# SAMA7D65D2GN8 register map
Vendor: Microchip Technology; Series: SAMA7D6; File version: 0
Registers are 32-bit, read-write, reset 0x0 unless marked. A register's access mark holds for its fields unless they carry their own. Offsets are from the block's base; [hi:lo] are bit positions; {n}, {i} and the like mark numbered series; 'fields as' and 'values as' point back to an identical list.

## SSC0 — Synchronous Serial Controller
Base 0xE180C000; register names take the prefix SSC_
Same registers: SSC1 0xE2010000
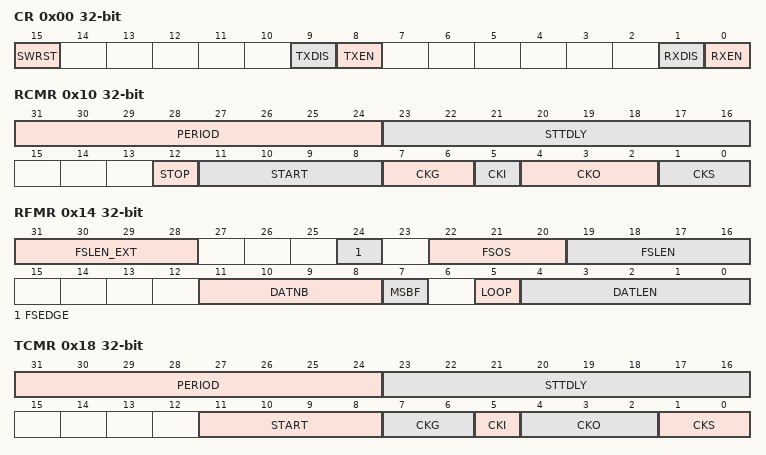
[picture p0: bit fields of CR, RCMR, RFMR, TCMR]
0x00 CR wo — Control Register
  [15] SWRST — Software Reset
    0=No effect; 1=Performs a software reset. Has priority on any other bit in SSC_CR.
  [9] TXDIS — Transmit Disable
    0=No effect; 1=Disables Transmit. If a character is currently being transmitted, disables at end of current character transmission.
  [8] TXEN — Transmit Enable
    0=No effect; 1=Enables Transmit if TXDIS is not set
  [1] RXDIS — Receive Disable
    0=No effect; 1=Disables Receive. If a character is currently being received, disables at end of current character reception.
  [0] RXEN — Receive Enable
    0=No effect; 1=Enables Receive if RXDIS is not set
0x04 CMR — Clock Mode Register
  [11:0] DIV — Clock Divider
    0=The Clock Divider is not active
0x10 RCMR — Receive Clock Mode Register
  [31:24] PERIOD — Receive Period Divider Selection
  [23:16] STTDLY — Receive Start Delay
  [12] STOP — Receive Stop Selection
    0=After completion of a data transfer when starting with a Compare 0, the receiver stops the data transfer and waits for a new compare 0; 1=After starting a receive with a Compare 0, the receiver operates in a continuous mode until a Compare 1 is detected
  [11:8] START — Receive Start Selection
    0=CONTINUOUS (Continuous, as soon as the receiver is enabled, and immediately after the end of transfer of the previous data.); 1=TRANSMIT (Transmit start); 2=RF_LOW (Detection of a low level on RF signal); 3=RF_HIGH (Detection of a high level on RF signal); 4=RF_FALLING (Detection of a falling edge on RF signal); 5=RF_RISING (Detection of a rising edge on RF signal); 6=RF_LEVEL (Detection of any level change on RF signal); 7=RF_EDGE (Detection of any edge on RF signal); 8=CMP_0 (Compare 0)
  [7:6] CKG — Receive Clock Gating Selection
    0=CONTINUOUS (None); 1=EN_RF_LOW (Receive Clock enabled only if RF Low); 2=EN_RF_HIGH (Receive Clock enabled only if RF High)
  [5] CKI — Receive Clock Inversion
    0=The data inputs (Data and Frame Sync signals) are sampled on Receive Clock falling edge. The Frame Sync signal output is shifted out on Receive Clock rising edge.; 1=The data inputs (Data and Frame Sync signals) are sampled on Receive Clock rising edge. The Frame Sync signal output is shifted out on Receive Clock falling edge.
  [4:2] CKO — Receive Clock Output Mode Selection
    0=NONE (None, RK pin is an input); 1=CONTINUOUS (Continuous Receive Clock, RK pin is an output); 2=TRANSFER (Receive Clock only during data transfers, RK pin is an output)
  [1:0] CKS — Receive Clock Selection
    0=MCK (Divided Clock); 1=TK (TK Clock signal); 2=RK (RK pin)
0x14 RFMR — Receive Frame Mode Register
  [31:28] FSLEN_EXT — FSLEN Field Extension
  [24] FSEDGE — Frame Sync Edge Detection
    0=POSITIVE (Positive Edge Detection); 1=NEGATIVE (Negative Edge Detection)
  [22:20] FSOS — Receive Frame Sync Output Selection
    0=NONE (None, RF pin is an input); 1=NEGATIVE (Negative Pulse, RF pin is an output); 2=POSITIVE (Positive Pulse, RF pin is an output); 3=LOW (Driven Low during data transfer, RF pin is an output); 4=HIGH (Driven High during data transfer, RF pin is an output); 5=TOGGLING (Toggling at each start of data transfer, RF pin is an output)
  [19:16] FSLEN — Receive Frame Sync Length
  [11:8] DATNB — Data Number per Frame
  [7] MSBF — Most Significant Bit First
    0=The lowest significant bit of the data register is sampled first in the bit stream; 1=The most significant bit of the data register is sampled first in the bit stream
  [5] LOOP — Loop Mode
    0=Normal operating mode; 1=RD is driven by TD, RF is driven by TF and TK drives RK
  [4:0] DATLEN — Data Length
    0=Forbidden value (1-bit data length not supported)
0x18 TCMR — Transmit Clock Mode Register
  [31:24] PERIOD — Transmit Period Divider Selection
  [23:16] STTDLY — Transmit Start Delay
  [11:8] START — Transmit Start Selection
    0=CONTINUOUS (Continuous, as soon as a word is written in the SSC_THFR (if Transmit is enabled), and immediately after the end of transfer of the previous data); 1=RECEIVE (Receive start); 2=TF_LOW (Detection of a low level on TF signal); 3=TF_HIGH (Detection of a high level on TF signal); 4=TF_FALLING (Detection of a falling edge on TF signal); 5=TF_RISING (Detection of a rising edge on TF signal); 6=TF_LEVEL (Detection of any level change on TF signal); 7=TF_EDGE (Detection of any edge on TF signal)
  [7:6] CKG — Transmit Clock Gating Selection
    0=CONTINUOUS (None); 1=EN_TF_LOW (Transmit Clock enabled only if TF Low); 2=EN_TF_HIGH (Transmit Clock enabled only if TF High)
  [5] CKI — Transmit Clock Inversion
    0=The data outputs (Data and Frame Sync signals) are shifted out on Transmit Clock falling edge. The Frame Sync signal input is sampled on Transmit Clock rising edge.; 1=The data outputs (Data and Frame Sync signals) are shifted out on Transmit Clock rising edge. The Frame Sync signal input is sampled on Transmit Clock falling edge.
  [4:2] CKO — Transmit Clock Output Mode Selection
    0=NONE (None, TK pin is an input); 1=CONTINUOUS (Continuous Transmit Clock, TK pin is an output); 2=TRANSFER (Transmit Clock only during data transfers, TK pin is an output)
  [1:0] CKS — Transmit Clock Selection
    0=MCK (Divided Clock); 1=RK (RK Clock signal); 2=TK (TK pin)
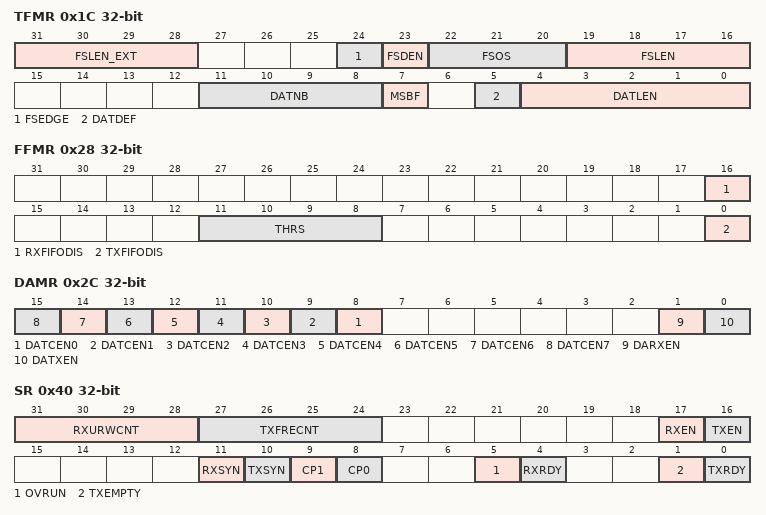
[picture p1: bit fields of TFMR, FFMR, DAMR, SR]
0x1C TFMR — Transmit Frame Mode Register
  [31:28] FSLEN_EXT — FSLEN Field Extension
  [24] FSEDGE — Frame Sync Edge Detection
    values as RFMR.FSEDGE
  [23] FSDEN — Frame Sync Data Enable
    0=The TD line is driven with the default value during the Transmit Frame Sync signal; 1=SSC_TSHR value is shifted out during the transmission of the Transmit Frame Sync signal
  [22:20] FSOS — Transmit Frame Sync Output Selection
    0=NONE (None, TF pin is an input); 1=NEGATIVE (Negative Pulse, TF pin is an output); 2=POSITIVE (Positive Pulse, TF pin is an output); 3=LOW (Driven Low during data transfer); 4=HIGH (Driven High during data transfer); 5=TOGGLING (Toggling at each start of data transfer)
  [19:16] FSLEN — Transmit Frame Sync Length
  [11:8] DATNB — Data Number per Frame
  [7] MSBF — Most Significant Bit First
    0=The lowest significant bit of the data register is shifted out first in the bit stream; 1=The most significant bit of the data register is shifted out first in the bit stream
  [5] DATDEF — Data Default Value
  [4:0] DATLEN — Data Length
    0=Forbidden value (1-bit data length not supported)
0x20 RHFR ro — Receive Holding FIFO Register
  [31:0] RDAT — Receive Data
0x24 THFR wo — Transmit Holding FIFO Register
  [31:0] TDAT — Transmit Data
0x28 FFMR — FIFO Mode Register
  [16] RXFIFODIS — Receive FIFO Disable
    0=The receive FIFO is enabled; 1=The receive FIFO is disabled. Only a single entry Receive Holding register is available instead.
  [11:8] THRS — Transmit Start Threshold
  [0] TXFIFODIS — Transmit FIFO Disable
    0=The transmit FIFO is enabled; 1=The transmit FIFO is disabled. Only a single entry Transmit Holding register is available instead.
0x2C DAMR — Direct Access Mode Register
  [n+8] DATCEN{n} (n=0..7) — Direct Access Transmit Channel {n} Enable
    0=Channel x from the ASRC direct audio stream is not transmitted on the SSC physical output line; 1=Channel x from the ASRC direct audio stream is transmitted on the SSC physical output line
  [1] DARXEN — Direct Access Receive Enable
    1=The ASRC can be directly loaded with the audio samples from the SSC physical output line without software or DMA intervention
  [0] DATXEN — Direct Access Transmit Enable
    1=The Asynchronous Sample Rate Converter (ASRC) can directly transmit the converted audio samples on the SSC physical output line without software or DMA intervention
0x30 RSHR ro — Receive Sync. Holding Register
  [15:0] RSDAT — Receive Synchronization Data
0x34 TSHR — Transmit Sync. Holding Register
  [15:0] TSDAT — Transmit Synchronization Data
0x38 RC0R — Receive Compare 0 Register
  [15:0] CP0 — Receive Compare Data 0
0x3C RC1R — Receive Compare 1 Register
  [15:0] CP1 — Receive Compare Data 1
0x40 SR ro — Status Register
  [31:28] RXURWCNT — Receive FIFO Unread Word Count
  [27:24] TXFRECNT — Transmit FIFO Free Entries Count
  [17] RXEN — Receive Enable
    0=Receive is disabled; 1=Receive is enabled
  [16] TXEN — Transmit Enable
    0=Transmit is disabled; 1=Transmit is enabled
  [11] RXSYN — Receive Sync
    0=No Rx Sync has occurred since the last read of the Status register; 1=An Rx Sync has occurred since the last read of the Status register
  [10] TXSYN — Transmit Sync
    0=No Tx Sync has occurred since the last read of the Status register; 1=A Tx Sync has occurred since the last read of the Status register
  [9] CP1 — Compare 1
    0=No compare 1 has occurred since the last read of the Status register; 1=A compare 1 has occurred since the last read of the Status register
  [8] CP0 — Compare 0
    0=No compare 0 has occurred since the last read of the Status register; 1=A compare 0 has occurred since the last read of the Status register
  [5] OVRUN — Receive Overrun
    0=No data has been loaded in SSC_RHFR while previous data has not been read since the last read of the Status register; 1=Data has been loaded in SSC_RHFR while previous data has not yet been read since the last read of the Status register
  [4] RXRDY — Receive Ready
    0=SSC_RHFR is empty; 1=Data has been received and loaded in SSC_RHFR
  [1] TXEMPTY — Transmit Empty
    0=Data remains in SSC_THFR or is currently transmitted from TSR; 1=Last data written in SSC_THFR has been loaded in TSR and last data loaded in TSR has been transmitted
  [0] TXRDY — Transmit Ready
    0=Data has been loaded in SSC_THFR and is waiting to be loaded in the Transmit Shift register (TSR); 1=SSC_THFR is empty
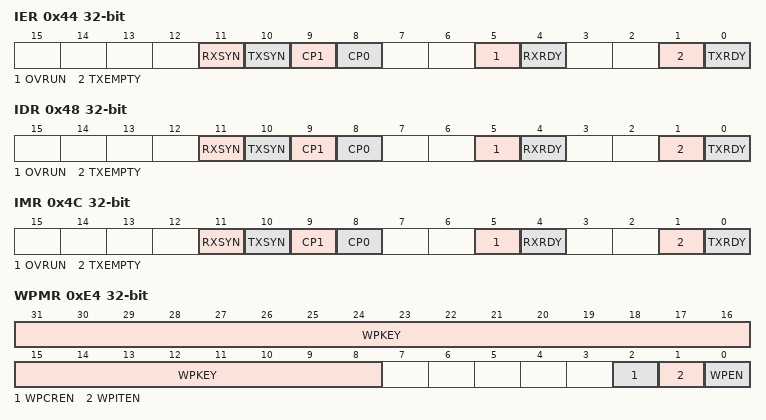
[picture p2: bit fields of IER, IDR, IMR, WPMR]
0x44 IER wo — Interrupt Enable Register
  [11] RXSYN — Rx Sync Interrupt Enable
  [10] TXSYN — Tx Sync Interrupt Enable
  [9] CP1 — Compare 1 Interrupt Enable
  [8] CP0 — Compare 0 Interrupt Enable
  [5] OVRUN — Receive Overrun Interrupt Enable
  [4] RXRDY — Receive Ready Interrupt Enable
  [1] TXEMPTY — Transmit Empty Interrupt Enable
  [0] TXRDY — Transmit Ready Interrupt Enable
0x48 IDR wo — Interrupt Disable Register
  [11] RXSYN — Rx Sync Interrupt Disable
  [10] TXSYN — Tx Sync Interrupt Disable
  [9] CP1 — Compare 1 Interrupt Disable
  [8] CP0 — Compare 0 Interrupt Disable
  [5] OVRUN — Receive Overrun Interrupt Disable
  [4] RXRDY — Receive Ready Interrupt Disable
  [1] TXEMPTY — Transmit Empty Interrupt Disable
  [0] TXRDY — Transmit Ready Interrupt Disable
0x4C IMR ro — Interrupt Mask Register
  [11] RXSYN — Rx Sync Interrupt Mask
  [10] TXSYN — Tx Sync Interrupt Mask
  [9] CP1 — Compare 1 Interrupt Mask
  [8] CP0 — Compare 0 Interrupt Mask
  [5] OVRUN — Receive Overrun Interrupt Mask
  [4] RXRDY — Receive Ready Interrupt Mask
  [1] TXEMPTY — Transmit Empty Interrupt Mask
  [0] TXRDY — Transmit Ready Interrupt Mask
0xE4 WPMR — Write Protection Mode Register
  [31:8] WPKEY — Write Protection Key
    0x535343=PASSWD (Writing any other value in this field aborts the write operation of the WPEN,WPITEN,WPCREN bits. Always reads as 0.)
  [2] WPCREN — Write Protection Control Enable
    0=Disables the write protection of the control register if WPKEY corresponds to 0x535343 ('SSC' in ASCII); 1=Enables the write protection of the control register if WPKEY corresponds to 0x535343 ('SSC' in ASCII)
  [1] WPITEN — Write Protection Interrupt Enable
    0=Disables the write protection of the interrupt registers if WPKEY corresponds to 0x535343 ('SSC' in ASCII); 1=Enables the write protection of the interrupt registers if WPKEY corresponds to 0x535343 ('SSC' in ASCII)
  [0] WPEN — Write Protection Enable
    0=Disables the write protection of the configuration registers if WPKEY corresponds to 0x535343 ('SSC' in ASCII); 1=Enables the write protection of the configuration registers if WPKEY corresponds to 0x535343 ('SSC' in ASCII)
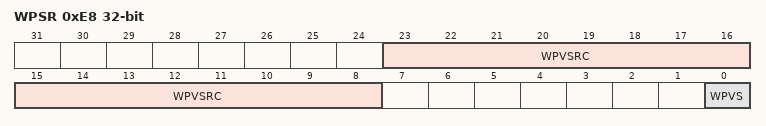
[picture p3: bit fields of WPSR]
0xE8 WPSR ro — Write Protection Status Register
  [23:8] WPVSRC — Write Protect Violation Source
  [0] WPVS — Write Protection Violation Status
    0=No write protection violation has occurred since the last read of the SSC_WPSR; 1=A write protection violation has occurred since the last read of the SSC_WPSR. If this violation is an unauthorized attempt to write a protected register, the associated violation is reported into field WPVSRC.
